VERSION "EverVance Vehicle Demo 1.0"

NS_ :

BS_:

BU_: VCU BCM ABS EPS IPC TBOX

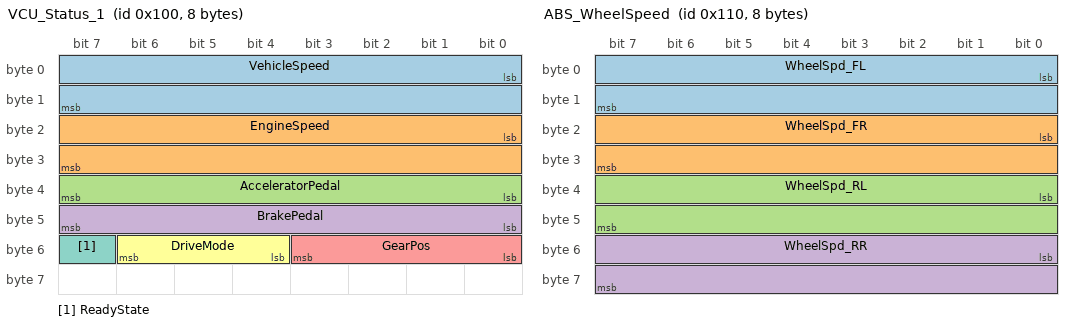
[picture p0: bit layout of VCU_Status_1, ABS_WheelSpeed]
BO_ 256 VCU_Status_1: 8 VCU
 SG_ VehicleSpeed : 0|16@1+ (0.01,0) [0|300] "km/h"
 SG_ EngineSpeed : 16|16@1+ (0.25,0) [0|16000] "rpm"
 SG_ AcceleratorPedal : 32|8@1+ (0.4,0) [0|100] "%"
 SG_ BrakePedal : 40|8@1+ (0.4,0) [0|100] "%"
 SG_ GearPos : 48|4@1+ (1,0) [0|15] ""
 SG_ DriveMode : 52|3@1+ (1,0) [0|7] ""
 SG_ ReadyState : 55|1@1+ (1,0) [0|1] ""

BO_ 272 ABS_WheelSpeed: 8 ABS
 SG_ WheelSpd_FL : 0|16@1+ (0.01,0) [0|300] "km/h"
 SG_ WheelSpd_FR : 16|16@1+ (0.01,0) [0|300] "km/h"
 SG_ WheelSpd_RL : 32|16@1+ (0.01,0) [0|300] "km/h"
 SG_ WheelSpd_RR : 48|16@1+ (0.01,0) [0|300] "km/h"

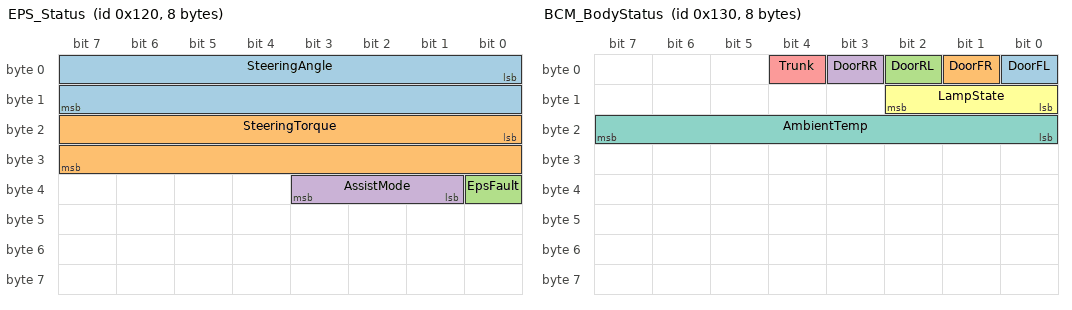
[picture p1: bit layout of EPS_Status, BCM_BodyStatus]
BO_ 288 EPS_Status: 8 EPS
 SG_ SteeringAngle : 0|16@1- (0.1,0) [-780|780] "deg"
 SG_ SteeringTorque : 16|16@1- (0.1,0) [-50|50] "Nm"
 SG_ EpsFault : 32|1@1+ (1,0) [0|1] ""
 SG_ AssistMode : 33|3@1+ (1,0) [0|7] ""

BO_ 304 BCM_BodyStatus: 8 BCM
 SG_ DoorFL : 0|1@1+ (1,0) [0|1] ""
 SG_ DoorFR : 1|1@1+ (1,0) [0|1] ""
 SG_ DoorRL : 2|1@1+ (1,0) [0|1] ""
 SG_ DoorRR : 3|1@1+ (1,0) [0|1] ""
 SG_ Trunk : 4|1@1+ (1,0) [0|1] ""
 SG_ LampState : 8|3@1+ (1,0) [0|7] ""
 SG_ AmbientTemp : 16|8@1- (1,-40) [-40|87] "degC"

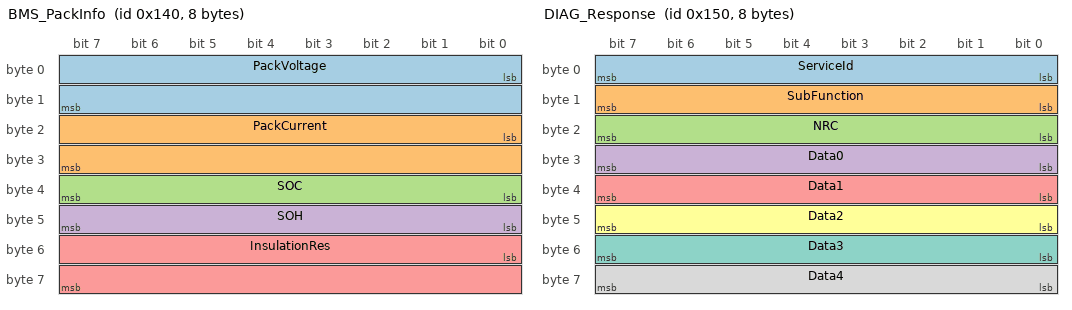
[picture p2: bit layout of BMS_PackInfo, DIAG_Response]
BO_ 320 BMS_PackInfo: 8 TBOX
 SG_ PackVoltage : 0|16@1+ (0.1,0) [0|1000] "V"
 SG_ PackCurrent : 16|16@1- (0.1,0) [-500|500] "A"
 SG_ SOC : 32|8@1+ (0.4,0) [0|100] "%"
 SG_ SOH : 40|8@1+ (0.4,0) [0|100] "%"
 SG_ InsulationRes : 48|16@1+ (1,0) [0|65535] "kOhm"

BO_ 336 DIAG_Response: 8 IPC
 SG_ ServiceId : 0|8@1+ (1,0) [0|255] ""
 SG_ SubFunction : 8|8@1+ (1,0) [0|255] ""
 SG_ NRC : 16|8@1+ (1,0) [0|255] ""
 SG_ Data0 : 24|8@1+ (1,0) [0|255] ""
 SG_ Data1 : 32|8@1+ (1,0) [0|255] ""
 SG_ Data2 : 40|8@1+ (1,0) [0|255] ""
 SG_ Data3 : 48|8@1+ (1,0) [0|255] ""
 SG_ Data4 : 56|8@1+ (1,0) [0|255] ""
